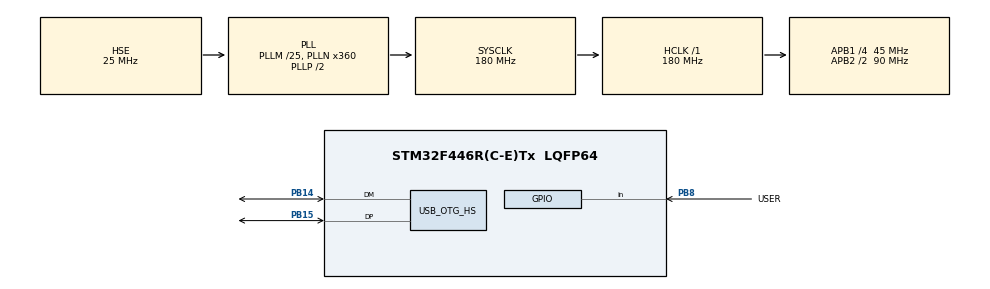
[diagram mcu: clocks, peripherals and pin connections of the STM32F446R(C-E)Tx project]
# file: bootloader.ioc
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Mcu.Family=STM32F4
Mcu.Name=STM32F446R(C-E)Tx
Mcu.Package=LQFP64
NVIC.OTG_HS_IRQn=true\:0\:0\:false\:false\:true\:true\:true\:true
NVIC.PriorityGroup=NVIC_PRIORITYGROUP_4
PA13.Mode=Trace_Asynchronous_SW
PA13.Signal=SYS_JTMS-SWDIO
PA14.Mode=Trace_Asynchronous_SW
PA14.Signal=SYS_JTCK-SWCLK
PB14.Mode=Device_Only_FS
PB14.Signal=USB_OTG_HS_DM
PB15.Mode=Device_Only_FS
PB15.Signal=USB_OTG_HS_DP
PB3.Mode=Trace_Asynchronous_SW
PB3.Signal=SYS_JTDO-SWO
PB8.GPIO_Label=USER
PB8.Signal=GPIO_Input
PH0-OSC_IN.Mode=HSE-External-Oscillator
PH0-OSC_IN.Signal=RCC_OSC_IN
PH1-OSC_OUT.Mode=HSE-External-Oscillator
PH1-OSC_OUT.Signal=RCC_OSC_OUT
ProjectManager.HeapSize=0x200
ProjectManager.StackSize=0x400
ProjectManager.TargetToolchain=STM32CubeIDE
RCC.AHBFreq_Value=180000000
RCC.APB1CLKDivider=RCC_HCLK_DIV4
RCC.APB1Freq_Value=45000000
RCC.APB1TimFreq_Value=90000000
RCC.APB2CLKDivider=RCC_HCLK_DIV2
RCC.APB2Freq_Value=90000000
RCC.APB2TimFreq_Value=180000000
RCC.CortexFreq_Value=180000000
RCC.HCLKFreq_Value=180000000
RCC.HSE_VALUE=25000000
RCC.PLLM=25
RCC.PLLN=360
RCC.PLLSAIM=25
RCC.PLLSAIP=RCC_PLLSAIP_DIV4
RCC.PLLSourceVirtual=RCC_PLLSOURCE_HSE
RCC.SYSCLKFreq_VALUE=180000000
RCC.SYSCLKSource=RCC_SYSCLKSOURCE_PLLCLK
RCC.USBCLockSelection=RCC_CLK48CLKSOURCE_PLLSAIP
RCC.USBFreq_Value=48000000
RCC.VCOOutputFreq_Value=360000000
USB_OTG_HS.VirtualMode-Device_Only_FS=Device_Only_FS
VP_CRC_VS_CRC.Mode=CRC_Activate
board=custom

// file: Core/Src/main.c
/* USER CODE BEGIN Header */
/**
 ******************************************************************************
 * @file           : main.c
 * @brief          : Main program body
 ******************************************************************************
 * @attention
 *
 * Copyright (c) 2024 STMicroelectronics.
 * All rights reserved.
 *
 * This software is licensed under terms that can be found in the LICENSE file
 * in the root directory of this software component.
 * If no LICENSE file comes with this software, it is provided AS-IS.
 *
 ******************************************************************************
 */
/* USER CODE END Header */
#include "main.h"

/* USER CODE BEGIN Includes */

#include "bootloader.h"

/* USER CODE END Includes */

CRC_HandleTypeDef hcrc;

PCD_HandleTypeDef hpcd_USB_OTG_HS;

void SystemClock_Config(void);
static void MX_GPIO_Init(void);
static void MX_CRC_Init(void);
static void MX_USB_OTG_HS_PCD_Init(void);

int main(void) {

  /* MCU Configuration--------------------------------------------------------*/

  /* Reset of all peripherals, Initializes the Flash interface and the Systick.
   */
  HAL_Init();

  /* Configure the system clock */
  SystemClock_Config();

  /* Initialize all configured peripherals */
  MX_GPIO_Init();
  MX_CRC_Init();
  MX_USB_OTG_HS_PCD_Init();
  /* USER CODE BEGIN 2 */

  bootloader_init();

  /* USER CODE END 2 */

  /* Infinite loop */
  /* USER CODE BEGIN WHILE */
  while (1) {
    bootloader_loop();
    /* USER CODE END WHILE */

  }
}

void SystemClock_Config(void) {
  RCC_OscInitTypeDef RCC_OscInitStruct = {0};
  RCC_ClkInitTypeDef RCC_ClkInitStruct = {0};

  /** Configure the main internal regulator output voltage
   */
  __HAL_RCC_PWR_CLK_ENABLE();
  __HAL_PWR_VOLTAGESCALING_CONFIG(PWR_REGULATOR_VOLTAGE_SCALE1);

  /** Initializes the RCC Oscillators according to the specified parameters
   * in the RCC_OscInitTypeDef structure.
   */
  RCC_OscInitStruct.OscillatorType = RCC_OSCILLATORTYPE_HSE;
  RCC_OscInitStruct.HSEState = RCC_HSE_ON;
  RCC_OscInitStruct.PLL.PLLState = RCC_PLL_ON;
  RCC_OscInitStruct.PLL.PLLSource = RCC_PLLSOURCE_HSE;
  RCC_OscInitStruct.PLL.PLLM = 25;
  RCC_OscInitStruct.PLL.PLLN = 360;
  RCC_OscInitStruct.PLL.PLLP = RCC_PLLP_DIV2;
  RCC_OscInitStruct.PLL.PLLQ = 2;
  RCC_OscInitStruct.PLL.PLLR = 2;
  if (HAL_RCC_OscConfig(&RCC_OscInitStruct) != HAL_OK) {
    Error_Handler();
  }

  /** Activate the Over-Drive mode
   */
  if (HAL_PWREx_EnableOverDrive() != HAL_OK) {
    Error_Handler();
  }

  /** Initializes the CPU, AHB and APB buses clocks
   */
  RCC_ClkInitStruct.ClockType = RCC_CLOCKTYPE_HCLK | RCC_CLOCKTYPE_SYSCLK |
                                RCC_CLOCKTYPE_PCLK1 | RCC_CLOCKTYPE_PCLK2;
  RCC_ClkInitStruct.SYSCLKSource = RCC_SYSCLKSOURCE_PLLCLK;
  RCC_ClkInitStruct.AHBCLKDivider = RCC_SYSCLK_DIV1;
  RCC_ClkInitStruct.APB1CLKDivider = RCC_HCLK_DIV4;
  RCC_ClkInitStruct.APB2CLKDivider = RCC_HCLK_DIV2;

  if (HAL_RCC_ClockConfig(&RCC_ClkInitStruct, FLASH_LATENCY_5) != HAL_OK) {
    Error_Handler();
  }
}

static void MX_CRC_Init(void) {

  hcrc.Instance = CRC;
  if (HAL_CRC_Init(&hcrc) != HAL_OK) {
    Error_Handler();
  }
}

static void MX_USB_OTG_HS_PCD_Init(void) {

  hpcd_USB_OTG_HS.Instance = USB_OTG_HS;
  hpcd_USB_OTG_HS.Init.dev_endpoints = 8;
  hpcd_USB_OTG_HS.Init.speed = PCD_SPEED_FULL;
  hpcd_USB_OTG_HS.Init.dma_enable = DISABLE;
  hpcd_USB_OTG_HS.Init.phy_itface = USB_OTG_EMBEDDED_PHY;
  hpcd_USB_OTG_HS.Init.Sof_enable = DISABLE;
  hpcd_USB_OTG_HS.Init.low_power_enable = DISABLE;
  hpcd_USB_OTG_HS.Init.lpm_enable = DISABLE;
  hpcd_USB_OTG_HS.Init.vbus_sensing_enable = DISABLE;
  hpcd_USB_OTG_HS.Init.use_dedicated_ep1 = DISABLE;
  hpcd_USB_OTG_HS.Init.use_external_vbus = DISABLE;
  if (HAL_PCD_Init(&hpcd_USB_OTG_HS) != HAL_OK) {
    Error_Handler();
  }
}

static void MX_GPIO_Init(void) {
  GPIO_InitTypeDef GPIO_InitStruct = {0};

  /* GPIO Ports Clock Enable */
  __HAL_RCC_GPIOH_CLK_ENABLE();
  __HAL_RCC_GPIOB_CLK_ENABLE();
  __HAL_RCC_GPIOA_CLK_ENABLE();

  /*Configure GPIO pin : USER_Pin */
  GPIO_InitStruct.Pin = USER_Pin;
  GPIO_InitStruct.Mode = GPIO_MODE_INPUT;
  GPIO_InitStruct.Pull = GPIO_NOPULL;
  HAL_GPIO_Init(USER_GPIO_Port, &GPIO_InitStruct);

}

void Error_Handler(void) {
  __disable_irq();
  while (1) {
  }
}

#ifdef USE_FULL_ASSERT
/**
 * @brief  Reports the name of the source file and the source line number
 *         where the assert_param error has occurred.
 * @param  file: pointer to the source file name
 * @param  line: assert_param error line source number
 * @retval None
 */
void assert_failed(uint8_t *file, uint32_t line) {
  /* USER CODE BEGIN 6 */
  /* User can add his own implementation to report the file name and line
     number, ex: printf("Wrong parameters value: file %s on line %d\r\n", file,
     line) */
  /* USER CODE END 6 */
}
#endif /* USE_FULL_ASSERT */
